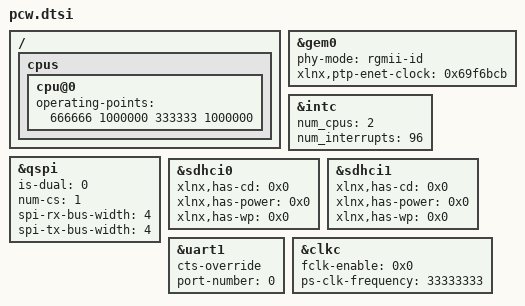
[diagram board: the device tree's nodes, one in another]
/*
 * CAUTION: This file is automatically generated by Xilinx.
 * Version: XSCT 2025.1
 * Today is: Tue Aug  4 12:06:56 2026
 */


/ {
	cpus {
		cpu@0 {
			operating-points = <666666 1000000 333333 1000000>;
		};
	};
};
&gem0 {
	phy-mode = "rgmii-id";
	status = "okay";
	xlnx,ptp-enet-clock = <0x69f6bcb>;
};
&intc {
	num_cpus = <2>;
	num_interrupts = <96>;
};
&qspi {
	is-dual = <0>;
	num-cs = <1>;
	spi-rx-bus-width = <4>;
	spi-tx-bus-width = <4>;
	status = "okay";
};
&sdhci0 {
	status = "okay";
	xlnx,has-cd = <0x0>;
	xlnx,has-power = <0x0>;
	xlnx,has-wp = <0x0>;
};
&sdhci1 {
	status = "okay";
	xlnx,has-cd = <0x0>;
	xlnx,has-power = <0x0>;
	xlnx,has-wp = <0x0>;
};
&uart1 {
	cts-override ;
	device_type = "serial";
	port-number = <0>;
	status = "okay";
};
&clkc {
	fclk-enable = <0x0>;
	ps-clk-frequency = <33333333>;
};
